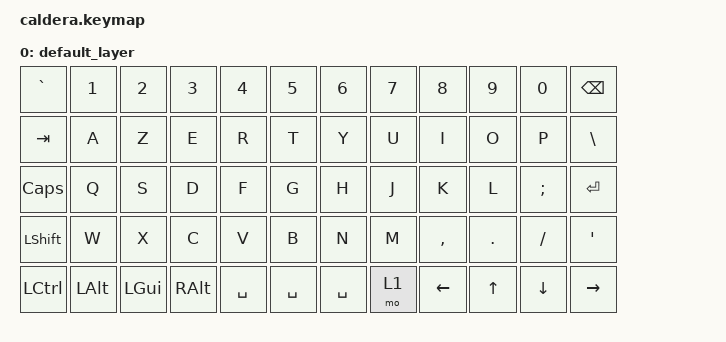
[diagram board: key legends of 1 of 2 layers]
#include <behaviors.dtsi>
#include <dt-bindings/zmk/bt.h>
#include <dt-bindings/zmk/keys.h>

/ {
    keymap {
        compatible = "zmk,keymap";

        default_layer {
            // ---------------------------------------------------------------------------------
            // |   `  |  1  |  2  |  3  |  4  |  5  |     |  6  |  7  |  8  |  9  |  0  | BKSP |
            // |  TAB |  A  |  Z  |  E  |  R  |  T  |     |  Y  |  U  |  I  |  O  |  P  |  \   |
            // | CAPS |  Q  |  S  |  D  |  F  |  G  |     |  H  |  J  |  K  |  L  |  ;  |  ENT |
            // | SHFT |  W  |  X  |  C  |  V  |  B  |     |  N  |  M  |  ,  |  .  |  /  | APOS |
            // | CTRL | ALT | GUI | SPC | SPC | SPC |     | SPC | LOW |LARW |DARW |UARW | RARW |

            bindings = <
&kp GRAVE         &kp N1        &kp N2        &kp N3         &kp N4     &kp N5       &kp N6     &kp N7  &kp N8          &kp N9        &kp N0          &kp BSPC
&kp TAB           &kp A         &kp Z         &kp E          &kp R      &kp T        &kp Y      &kp U   &kp I           &kp O         &kp P           &kp BSLH
&kp CAPS          &kp Q         &kp S         &kp D          &kp F      &kp G        &kp H      &kp J   &kp K           &kp L         &kp SEMI        &kp RET
&kp LSHFT         &kp W         &kp X         &kp C          &kp V      &kp B        &kp N      &kp M   &kp COMMA       &kp DOT       &kp FSLH        &kp APOS
&kp LEFT_CONTROL  &kp LEFT_ALT  &kp LEFT_GUI  &kp RIGHT_ALT  &kp SPACE  &kp SPACE    &kp SPACE  &mo 1   &kp LEFT_ARROW  &kp UP_ARROW  &kp DOWN_ARROW  &kp RIGHT_ARROW
            >;
        };

        lower_layer {
            // ------------------------------------------------------------------------------------------------------------
            // |   F1  |  F2   |  F3   |  F4   |  F5   |  F6   |          |   F7  |  F8   |  F9   |  F10  |  F11  | F12   |
            // |       |  BT1  |  BT2  |  BT3  |  BT4  |  BT5  |          |       |       |       |       |       | BTCLR |
            // |       |       |       | LPAR  | RPAR  |       |          |       | LBKT  | RBKT  |       |       |       |
            // |       |       |       |       |       |       |          |       |       |       |       |       |       |

            bindings = <
&kp F1  &kp F2        &kp F3        &kp F4        &kp F5        &kp F6          &kp F7  &kp F8    &kp F9    &kp F10    &kp F11    &kp F12
&trans  &bt BT_SEL 0  &bt BT_SEL 1  &bt BT_SEL 2  &bt BT_SEL 3  &bt BT_SEL 4    &trans  &trans    &trans    &trans     &trans     &bt BT_CLR
&trans  &trans        &trans        &kp LPAR      &kp RPAR      &trans          &trans  &kp LBKT  &kp RBKT  &kp MINUS  &kp EQUAL  &trans
&trans  &trans        &trans        &trans        &trans        &trans          &trans  &trans    &trans    &trans     &trans     &trans
            >;
        };
    };
};
